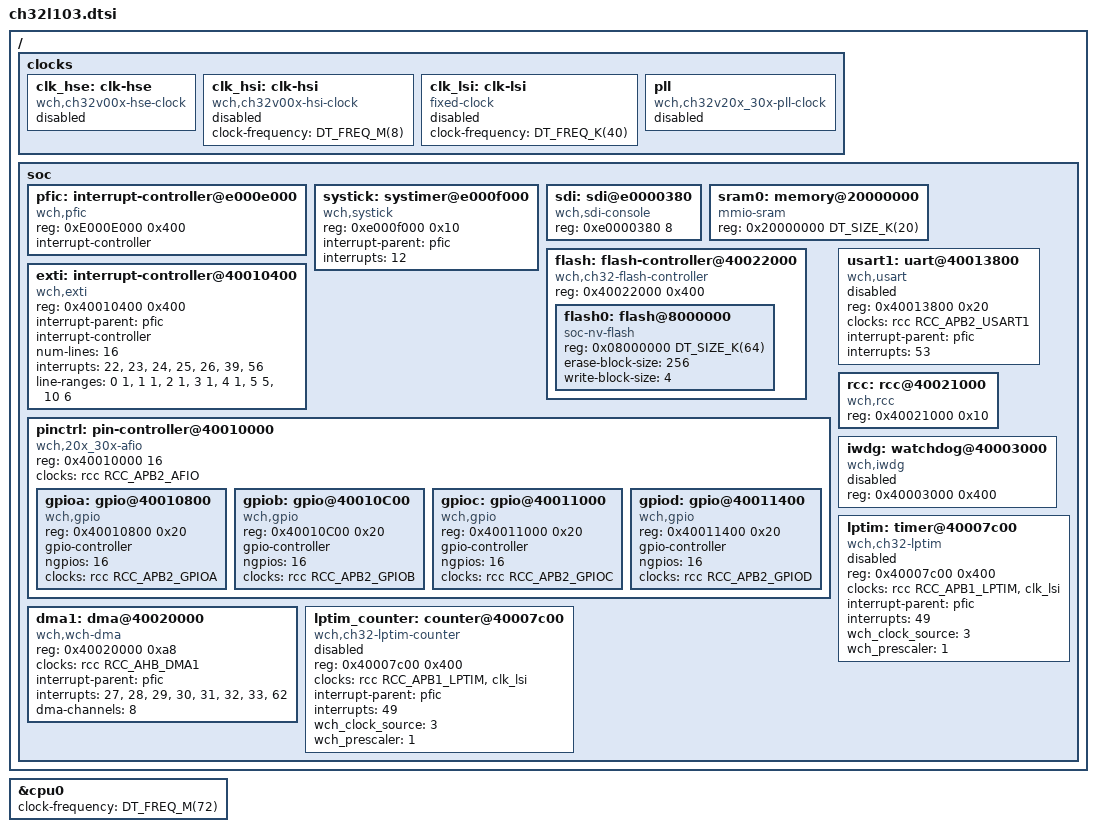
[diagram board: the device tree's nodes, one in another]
/*
 * Copyright (c) 2026 Scott King
 *
 * SPDX-License-Identifier: Apache-2.0
 */

#include <freq.h>
#include <mem.h>
#include <wch/qingke-v4c.dtsi>
#include <zephyr/dt-bindings/gpio/gpio.h>
#include <zephyr/dt-bindings/clock/ch32l103_clock.h>

/ {
	clocks {
		clk_hse: clk-hse {
			#clock-cells = <0>;
			compatible = "wch,ch32v00x-hse-clock";
			status = "disabled";
		};

		clk_hsi: clk-hsi {
			#clock-cells = <0>;
			compatible = "wch,ch32v00x-hsi-clock";
			clock-frequency = <DT_FREQ_M(8)>;
			status = "disabled";
		};

		clk_lsi: clk-lsi {
			#clock-cells = <0>;
			compatible = "fixed-clock";
			clock-frequency = <DT_FREQ_K(40)>;
			status = "disabled";
		};

		pll: pll {
			#clock-cells = <0>;
			compatible = "wch,ch32v20x_30x-pll-clock";
			status = "disabled";
		};
	};

	soc: soc {
		pfic: interrupt-controller@e000e000 {
			compatible = "wch,pfic";
			reg = <0xE000E000 0x400>;
			interrupt-controller;
			#interrupt-cells = <1>;
			status = "okay";
		};

		systick: systimer@e000f000 {
			compatible = "wch,systick";
			reg = <0xe000f000 0x10>;
			status = "okay";
			interrupt-parent = <&pfic>;
			interrupts = <12>;
		};

		sdi: sdi@e0000380 {
			compatible = "wch,sdi-console";
			reg = <0xe0000380 8>;
			status = "okay";
		};

		sram0: memory@20000000 {
			compatible = "mmio-sram";
			reg = <0x20000000 DT_SIZE_K(20)>;
		};

		flash: flash-controller@40022000 {
			compatible = "wch,ch32-flash-controller";
			status = "okay";
			reg = <0x40022000 0x400>;

			#address-cells = <1>;
			#size-cells = <1>;

			flash0: flash@8000000 {
				compatible = "soc-nv-flash";
				reg = <0x08000000 DT_SIZE_K(64)>;
				erase-block-size = <256>;
				write-block-size = <4>;
			};
		};

		exti: interrupt-controller@40010400 {
			compatible = "wch,exti";
			reg = <0x40010400 0x400>;
			interrupt-parent = <&pfic>;
			interrupt-controller;
			#interrupt-cells = <1>;
			num-lines = <16>;
			interrupts = <22>, <23>, <24>, <25>, <26>, <39>, <56>;
			interrupt-names = "line0", "line1", "line2", "line3", "line4", "line5-9", "line10-15";
			line-ranges = <0 1>, <1 1>, <2 1>, <3 1>, <4 1>, <5 5>, <10 6>;
			status = "okay";
		};

		pinctrl: pin-controller@40010000 {
			compatible = "wch,20x_30x-afio";
			reg = <0x40010000 16>;
			#address-cells = <1>;
			#size-cells = <1>;
			clocks = <&rcc RCC_APB2_AFIO>;

			gpioa: gpio@40010800 {
				compatible = "wch,gpio";
				reg = <0x40010800 0x20>;
				gpio-controller;
				#gpio-cells = <2>;
				ngpios = <16>;
				clocks = <&rcc RCC_APB2_GPIOA>;
			};

			gpiob: gpio@40010C00 {
				compatible = "wch,gpio";
				reg = <0x40010C00 0x20>;
				gpio-controller;
				#gpio-cells = <2>;
				ngpios = <16>;
				clocks = <&rcc RCC_APB2_GPIOB>;
			};

			gpioc: gpio@40011000 {
				compatible = "wch,gpio";
				reg = <0x40011000 0x20>;
				gpio-controller;
				#gpio-cells = <2>;
				ngpios = <16>;
				clocks = <&rcc RCC_APB2_GPIOC>;
			};

			gpiod: gpio@40011400 {
				compatible = "wch,gpio";
				reg = <0x40011400 0x20>;
				gpio-controller;
				#gpio-cells = <2>;
				ngpios = <16>;
				clocks = <&rcc RCC_APB2_GPIOD>;
			};
		};

		usart1: uart@40013800 {
			compatible = "wch,usart";
			reg = <0x40013800 0x20>;
			clocks = <&rcc RCC_APB2_USART1>;
			interrupt-parent = <&pfic>;
			interrupts = <53>;
			status = "disabled";
		};

		rcc: rcc@40021000 {
			compatible = "wch,rcc";
			reg = <0x40021000 0x10>;
			#clock-cells = <1>;
			status = "okay";
		};

		dma1: dma@40020000 {
			compatible = "wch,wch-dma";
			reg = <0x40020000 0xa8>;
			clocks = <&rcc RCC_AHB_DMA1>;
			#dma-cells = <1>;
			interrupt-parent = <&pfic>;
			interrupts = <27>, <28>, <29>, <30>, <31>, <32>, <33>, <62>;
			dma-channels = <8>;
		};

		iwdg: watchdog@40003000 {
			compatible = "wch,iwdg";
			reg = <0x40003000 0x400>;
			status = "disabled";
		};

		lptim: timer@40007c00 {
			compatible = "wch,ch32-lptim";
			reg = <0x40007c00 0x400>;
			clocks = <&rcc RCC_APB1_LPTIM>, <&clk_lsi>;
			clock-names = "lptim", "clk_lsi";
			interrupt-parent = <&pfic>;
			interrupts = <49>;
			wch_clock_source = <3>; /* LSI */
			wch_prescaler = <1>;
			status = "disabled";
		};

		lptim_counter: counter@40007c00 {
			compatible = "wch,ch32-lptim-counter";
			reg = <0x40007c00 0x400>;
			clocks = <&rcc RCC_APB1_LPTIM>, <&clk_lsi>;
			clock-names = "lptim", "clk_lsi";
			interrupt-parent = <&pfic>;
			interrupts = <49>;
			wch_clock_source = <3>; /* LSI */
			wch_prescaler = <1>;
			status = "disabled";
		};
	};
};

&cpu0 {
	clock-frequency = <DT_FREQ_M(72)>;
};
